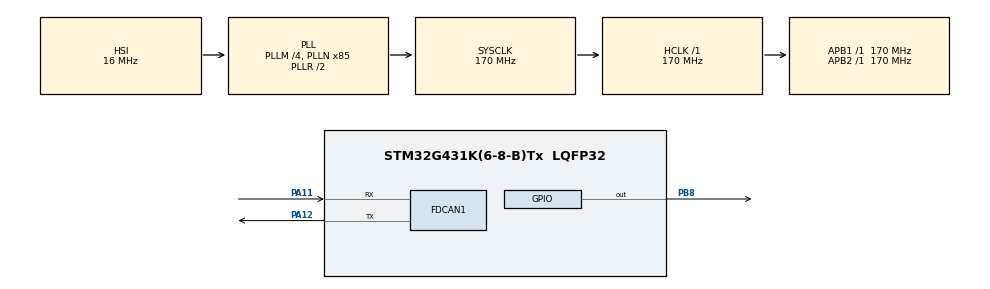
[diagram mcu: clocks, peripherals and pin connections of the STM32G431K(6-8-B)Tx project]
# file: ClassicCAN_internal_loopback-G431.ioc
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FDCAN1.CalculateBaudRateNominal=1000000
FDCAN1.CalculateTimeBitNominal=1000
FDCAN1.CalculateTimeQuantumNominal=100.0
FDCAN1.DataPrescaler=17
FDCAN1.DataTimeSeg1=8
FDCAN1.ExtFiltersNbr=0
FDCAN1.FrameFormat=FDCAN_FRAME_CLASSIC
FDCAN1.Mode=FDCAN_MODE_INTERNAL_LOOPBACK
FDCAN1.NominalPrescaler=17
FDCAN1.NominalTimeSeg1=8
FDCAN1.StdFiltersNbr=1
Mcu.Family=STM32G4
Mcu.Name=STM32G431K(6-8-B)Tx
Mcu.Package=LQFP32
NUCLEO-G431KB.LD2=true
NUCLEO-G431KB.VCP=true
NVIC.FDCAN1_IT0_IRQn=true\:0\:0\:false\:false\:true\:true\:true\:true
NVIC.PriorityGroup=NVIC_PRIORITYGROUP_4
PA11.Mode=FDCAN_Activate
PA11.Signal=FDCAN1_RX
PA12.Mode=FDCAN_Activate
PA12.Signal=FDCAN1_TX
PA13.GPIO_Label=T_SWDIO
PA13.Signal=SYS_JTMS-SWDIO
PA14.GPIO_Label=T_SWCLK
PA14.Signal=SYS_JTCK-SWCLK
PA2.Signal=USART2_TX
PA3.Signal=USART2_RX
PB3.GPIO_Label=T_SWO
PB3.Signal=SYS_JTDO-SWO
PB8-BOOT0.Signal=GPIO_Output
ProjectManager.HeapSize=0x200
ProjectManager.StackSize=0x400
ProjectManager.TargetToolchain=CMake
RCC.ADC12Freq_Value=170000000
RCC.AHBFreq_Value=170000000
RCC.APB1Freq_Value=170000000
RCC.APB1TimFreq_Value=170000000
RCC.APB2Freq_Value=170000000
RCC.APB2TimFreq_Value=170000000
RCC.CortexFreq_Value=170000000
RCC.EXTERNAL_CLOCK_VALUE=12288000
RCC.HCLKFreq_Value=170000000
RCC.HSE_VALUE=8000000
RCC.HSI48_VALUE=48000000
RCC.HSI_VALUE=16000000
RCC.LSE_VALUE=32768
RCC.PLLM=RCC_PLLM_DIV4
RCC.PLLN=85
RCC.SYSCLKFreq_VALUE=170000000
RCC.SYSCLKSource=RCC_SYSCLKSOURCE_PLLCLK
RCC.USBFreq_Value=170000000
RCC.VCOOutputFreq_Value=340000000
VP_NUCLEO-G431KB_VS_BSP_COMMON.Mode=COMMON
VP_SYS_VS_DBSignals.Mode=DisableDeadBatterySignals
board=NUCLEO-G431KB

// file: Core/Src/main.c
/* USER CODE BEGIN Header */
/**
 ******************************************************************************
 * @file           : main.c
 * @brief          : Main program body
 ******************************************************************************
 * @attention
 *
 * Copyright (c) 2025 STMicroelectronics.
 * All rights reserved.
 *
 * This software is licensed under terms that can be found in the LICENSE file
 * in the root directory of this software component.
 * If no LICENSE file comes with this software, it is provided AS-IS.
 *
 ******************************************************************************
 */
/* USER CODE END Header */
#include "main.h"

COM_InitTypeDef BspCOMInit;

FDCAN_HandleTypeDef hfdcan1;

void SystemClock_Config(void);
static void MX_GPIO_Init(void);
static void MX_FDCAN1_Init(void);

/* USER CODE BEGIN 0 */
void HAL_FDCAN_RxFifo0Callback(FDCAN_HandleTypeDef *hfdcan,
                               uint32_t RxFifo0ITs) {
  if ((RxFifo0ITs & FDCAN_IT_RX_FIFO0_NEW_MESSAGE) != 0) {
    FDCAN_RxHeaderTypeDef rx_header;
    uint8_t recv_data[8];
    if (HAL_FDCAN_GetRxMessage(hfdcan, FDCAN_RX_FIFO0, &rx_header, recv_data) !=
        HAL_OK) {
      return;
    }
    uint16_t id = rx_header.Identifier;
    printf("id: %d, ", id);
    for (int i = 0; i < 8; i++) {
      printf("recv_data[%d]: %d, ", i, recv_data[i]);
    }
    printf("\n");
  }
}
/* USER CODE END 0 */

int main(void) {

  /* MCU Configuration--------------------------------------------------------*/

  /* Reset of all peripherals, Initializes the Flash interface and the Systick.
   */
  HAL_Init();

  /* Configure the system clock */
  SystemClock_Config();

  /* Initialize all configured peripherals */
  MX_GPIO_Init();
  MX_FDCAN1_Init();
  /* USER CODE BEGIN 2 */
  FDCAN_FilterTypeDef sFilterConfig = {0};
  sFilterConfig.IdType = FDCAN_STANDARD_ID;
  sFilterConfig.FilterIndex = 0;
  sFilterConfig.FilterType = FDCAN_FILTER_MASK;
  sFilterConfig.FilterConfig = FDCAN_FILTER_TO_RXFIFO0;
  sFilterConfig.FilterID1 = 1;
  sFilterConfig.FilterID2 = 0b11111111111;
  if (HAL_FDCAN_ConfigFilter(&hfdcan1, &sFilterConfig) != HAL_OK) {
    Error_Handler();
  }
  HAL_FDCAN_ConfigGlobalFilter(&hfdcan1, FDCAN_REJECT, FDCAN_REJECT,
                               FDCAN_FILTER_REMOTE, FDCAN_FILTER_REMOTE);
  if (HAL_FDCAN_ActivateNotification(&hfdcan1, FDCAN_IT_RX_FIFO0_NEW_MESSAGE,
                                     0) != HAL_OK) {
    Error_Handler();
  }
  if (HAL_FDCAN_Start(&hfdcan1) != HAL_OK) {
    Error_Handler();
  }
  /* USER CODE END 2 */

  /* Initialize leds */
  BSP_LED_Init(LED_GREEN);

  /* Initialize COM1 port (115200, 8 bits (7-bit data + 1 stop bit), no parity
   */
  BspCOMInit.BaudRate = 115200;
  BspCOMInit.WordLength = COM_WORDLENGTH_8B;
  BspCOMInit.StopBits = COM_STOPBITS_1;
  BspCOMInit.Parity = COM_PARITY_NONE;
  BspCOMInit.HwFlowCtl = COM_HWCONTROL_NONE;
  if (BSP_COM_Init(COM1, &BspCOMInit) != BSP_ERROR_NONE) {
    Error_Handler();
  }

  /* Infinite loop */
  while (1) {

    /* USER CODE BEGIN 3 */
    FDCAN_TxHeaderTypeDef tx_header1;
    tx_header1.Identifier = 1;
    tx_header1.IdType = FDCAN_STANDARD_ID;
    tx_header1.TxFrameType = FDCAN_DATA_FRAME;
    tx_header1.DataLength = FDCAN_DLC_BYTES_8;
    tx_header1.ErrorStateIndicator = FDCAN_ESI_ACTIVE;
    tx_header1.BitRateSwitch = FDCAN_BRS_OFF;
    tx_header1.FDFormat = FDCAN_CLASSIC_CAN;
    tx_header1.TxEventFifoControl = FDCAN_NO_TX_EVENTS;
    tx_header1.MessageMarker = 0;
    uint8_t tx_data1[8] = {1, 1, 1, 1, 1, 1, 1, 1};
    HAL_FDCAN_AddMessageToTxFifoQ(&hfdcan1, &tx_header1, tx_data1);

    HAL_Delay(1000);

    FDCAN_TxHeaderTypeDef tx_header2;
    tx_header2.Identifier = 2;
    tx_header2.IdType = FDCAN_STANDARD_ID;
    tx_header2.TxFrameType = FDCAN_DATA_FRAME;
    tx_header2.DataLength = FDCAN_DLC_BYTES_8;
    tx_header2.ErrorStateIndicator = FDCAN_ESI_ACTIVE;
    tx_header2.BitRateSwitch = FDCAN_BRS_OFF;
    tx_header2.FDFormat = FDCAN_CLASSIC_CAN;
    tx_header2.TxEventFifoControl = FDCAN_NO_TX_EVENTS;
    tx_header2.MessageMarker = 0;
    uint8_t tx_data2[8] = {2, 2, 2, 2, 2, 2, 2, 2};
    HAL_FDCAN_AddMessageToTxFifoQ(&hfdcan1, &tx_header2, tx_data2);

    HAL_Delay(1000);
  }
  /* USER CODE END 3 */
}

void SystemClock_Config(void) {
  RCC_OscInitTypeDef RCC_OscInitStruct = {0};
  RCC_ClkInitTypeDef RCC_ClkInitStruct = {0};

  /** Configure the main internal regulator output voltage
   */
  HAL_PWREx_ControlVoltageScaling(PWR_REGULATOR_VOLTAGE_SCALE1_BOOST);

  /** Initializes the RCC Oscillators according to the specified parameters
   * in the RCC_OscInitTypeDef structure.
   */
  RCC_OscInitStruct.OscillatorType = RCC_OSCILLATORTYPE_HSI;
  RCC_OscInitStruct.HSIState = RCC_HSI_ON;
  RCC_OscInitStruct.HSICalibrationValue = RCC_HSICALIBRATION_DEFAULT;
  RCC_OscInitStruct.PLL.PLLState = RCC_PLL_ON;
  RCC_OscInitStruct.PLL.PLLSource = RCC_PLLSOURCE_HSI;
  RCC_OscInitStruct.PLL.PLLM = RCC_PLLM_DIV4;
  RCC_OscInitStruct.PLL.PLLN = 85;
  RCC_OscInitStruct.PLL.PLLP = RCC_PLLP_DIV2;
  RCC_OscInitStruct.PLL.PLLQ = RCC_PLLQ_DIV2;
  RCC_OscInitStruct.PLL.PLLR = RCC_PLLR_DIV2;
  if (HAL_RCC_OscConfig(&RCC_OscInitStruct) != HAL_OK) {
    Error_Handler();
  }

  /** Initializes the CPU, AHB and APB buses clocks
   */
  RCC_ClkInitStruct.ClockType = RCC_CLOCKTYPE_HCLK | RCC_CLOCKTYPE_SYSCLK |
                                RCC_CLOCKTYPE_PCLK1 | RCC_CLOCKTYPE_PCLK2;
  RCC_ClkInitStruct.SYSCLKSource = RCC_SYSCLKSOURCE_PLLCLK;
  RCC_ClkInitStruct.AHBCLKDivider = RCC_SYSCLK_DIV1;
  RCC_ClkInitStruct.APB1CLKDivider = RCC_HCLK_DIV1;
  RCC_ClkInitStruct.APB2CLKDivider = RCC_HCLK_DIV1;

  if (HAL_RCC_ClockConfig(&RCC_ClkInitStruct, FLASH_LATENCY_4) != HAL_OK) {
    Error_Handler();
  }
}

static void MX_FDCAN1_Init(void) {

  hfdcan1.Instance = FDCAN1;
  hfdcan1.Init.ClockDivider = FDCAN_CLOCK_DIV1;
  hfdcan1.Init.FrameFormat = FDCAN_FRAME_CLASSIC;
  hfdcan1.Init.Mode = FDCAN_MODE_INTERNAL_LOOPBACK;
  hfdcan1.Init.AutoRetransmission = DISABLE;
  hfdcan1.Init.TransmitPause = DISABLE;
  hfdcan1.Init.ProtocolException = DISABLE;
  hfdcan1.Init.NominalPrescaler = 17;
  hfdcan1.Init.NominalSyncJumpWidth = 1;
  hfdcan1.Init.NominalTimeSeg1 = 8;
  hfdcan1.Init.NominalTimeSeg2 = 1;
  hfdcan1.Init.DataPrescaler = 17;
  hfdcan1.Init.DataSyncJumpWidth = 1;
  hfdcan1.Init.DataTimeSeg1 = 8;
  hfdcan1.Init.DataTimeSeg2 = 1;
  hfdcan1.Init.StdFiltersNbr = 1;
  hfdcan1.Init.ExtFiltersNbr = 0;
  hfdcan1.Init.TxFifoQueueMode = FDCAN_TX_FIFO_OPERATION;
  if (HAL_FDCAN_Init(&hfdcan1) != HAL_OK) {
    Error_Handler();
  }
}

static void MX_GPIO_Init(void) {

  /* GPIO Ports Clock Enable */
  __HAL_RCC_GPIOA_CLK_ENABLE();
  __HAL_RCC_GPIOB_CLK_ENABLE();

}

/* USER CODE BEGIN Header */
/**
 ******************************************************************************
 * @file           : main.c
 * @brief          : Main program body
 ******************************************************************************
 * @attention
 *
 * Copyright (c) 2025 STMicroelectronics.
 * All rights reserved.
 *
 * This software is licensed under terms that can be found in the LICENSE file
 * in the root directory of this software component.
 * If no LICENSE file comes with this software, it is provided AS-IS.
 *
 ******************************************************************************
 */
/* USER CODE END Header */

void Error_Handler(void) {
  __disable_irq();
  while (1) {
  }
}

#ifdef USE_FULL_ASSERT
/**
 * @brief  Reports the name of the source file and the source line number
 *         where the assert_param error has occurred.
 * @param  file: pointer to the source file name
 * @param  line: assert_param error line source number
 * @retval None
 */
void assert_failed(uint8_t *file, uint32_t line) {
  /* USER CODE BEGIN 6 */
  /* User can add his own implementation to report the file name and line
     number, ex: printf("Wrong parameters value: file %s on line %d\r\n", file,
     line) */
  /* USER CODE END 6 */
}
#endif /* USE_FULL_ASSERT */
